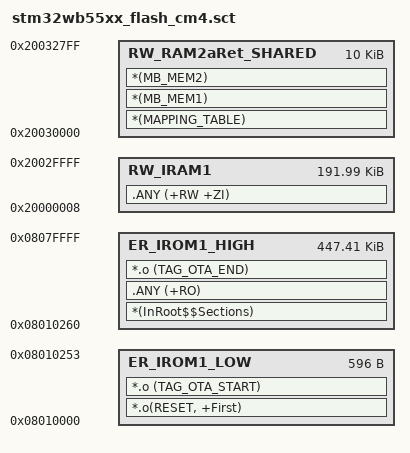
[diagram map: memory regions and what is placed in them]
; *************************************************************
; *** Scatter-Loading Description File generated by uVision ***
; *************************************************************

LR_IROM1 0x08010000 0x254 {    ; load region size_region
  ER_IROM1_LOW 0x08010000 0x254 {  ; load address = execution address
 *.o(RESET, +First)
 *.o (TAG_OTA_START) 
  }
  RW_IRAM1 0x20000008 0x0002FFF8  {  ; RW data
    .ANY (+RW +ZI)
  }
  RW_RAM2aRet_SHARED 0x20030000 0x2800  {  ; RW data
  *(MAPPING_TABLE)
    *(MB_MEM1)
    *(MB_MEM2)
  } 
}
LR_IROM3 0x8010260 0x6FDA0 {
  ER_IROM1_HIGH 0x8010260 0x6FDA0 {  ; load address = execution address	
	*(InRoot$$Sections)
	.ANY (+RO)  
	*.o (TAG_OTA_END)	
  }
  }
